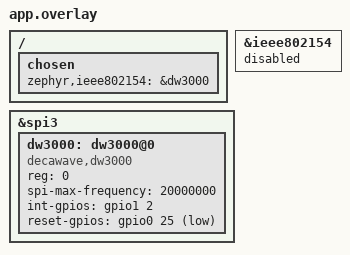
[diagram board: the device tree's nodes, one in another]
/ {
	chosen {
		zephyr,ieee802154 = &dw3000;
	};
};

&ieee802154 {
	status = "disabled";
};

&spi3 {
	status = "okay";

	dw3000: dw3000@0 {
		compatible = "decawave,dw3000";
		reg = <0>;
		spi-max-frequency = <20000000>;
		int-gpios = <&gpio1 2 GPIO_ACTIVE_HIGH>;
		reset-gpios = <&gpio0 25 GPIO_ACTIVE_LOW>;
		status = "okay";
	};
};
